# nrf9220_cellcore register map
Vendor: Nordic Semiconductor; Series: nRF92; File version: 1
CPU: CM33 r0p4, little endian, MPU, FPU, 3 interrupt priority bits, 480 interrupts, 8 SAU regions
Registers are 32-bit, read-write, reset 0x0 unless marked. A register's access mark holds for its fields unless they carry their own. Offsets are from the block's base; [hi:lo] are bit positions; lines under a group give offsets from that group; {n}, {i} and the like mark numbered series.

## LFCLKCALIBMEAS_NS — LFCLK calibration measurement 0
Base 0x44023000
Same registers: LFCLKCALIBMEAS_S 0x54023000
0x00 TASKS_START wo — Start Measuring
  [0] TASKS_START
    1=Trigger task
0x04 TASKS_STOP wo — Switch LfClkCalibMeas to STOPPED state. Brings LfClkCalibMeas from SHUTDOWN state to a configurable state before a measurement is launched.
  [0] TASKS_STOP
    1=Trigger task
0x08 TASKS_SHUTDOWN wo — Shut down LfClkCalibMeas
  [0] TASKS_SHUTDOWN
    1=Trigger task
0x100 EVENTS_COMPLETE — Measurement completed
  [0] EVENTS_COMPLETE
    0=NotGenerated (Event not generated); 1=Generated (Event generated)
0x300 INTEN — Enable or disable interrupt
  [0] COMPLETE — Enable or disable interrupt for event COMPLETE
    0=Disabled; 1=Enabled
0x304 INTENSET — Enable interrupt
  [0] COMPLETE — Write '1' to enable interrupt for event COMPLETE
    on read: 0=Disabled (Read: Disabled); 1=Enabled (Read: Enabled) | on write: 1=Set (Enable)
0x308 INTENCLR — Disable interrupt
  [0] COMPLETE — Write '1' to disable interrupt for event COMPLETE
    on read: 0=Disabled (Read: Disabled); 1=Enabled (Read: Enabled) | on write: 1=Clear (Disable)
0x30C INTPEND ro — Pending interrupts
  [0] COMPLETE — Read pending status of interrupt for event COMPLETE
    on read: 0=NotPending (Read: Not pending); 1=Pending (Read: Pending)
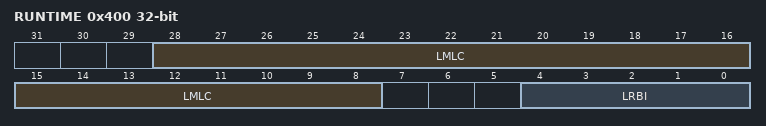
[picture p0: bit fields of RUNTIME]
0x400 RUNTIME ro — Runtime status of the measurement
  [28:8] LMLC — lastMeasuredLfCycle
  [4:0] LRBI — LastRingBufferIndex
{0x404+4i} LCMEAS[{i}] (i=0..19) group — Unspecified
  0x00 LCMEAS ro — Description cluster: LfClk measurement result for the series n
    [31:0] LCMEAS — LfClk measurement result for the series n
0x47C STATE ro — Current running state of the IP
  [1:0] STATE
    0=Shutdown (In SHUTDOWN state); 1=Stopped (In STOPPED state); 2=Running (In RUNNING state); 3=NotApplicable
0x500 MEASLEN — Length of the measurement
  [20:0] MEASLEN

## TIMEREVENTSYNCH_NS — Timer event synchronizer 0
Base 0x44024000
Same registers: TIMEREVENTSYNCH_S 0x54024000
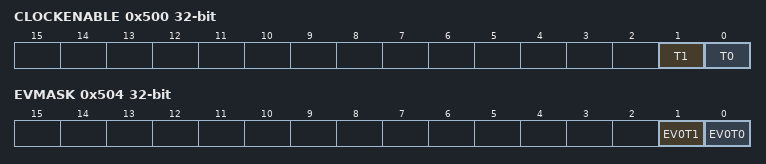
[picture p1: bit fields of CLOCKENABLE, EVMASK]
0x500 CLOCKENABLE — Enable synchronizer clock
  [1] T1 — Enable for clock ck_t1
    0=Disable clock ck_t1; 1=Enable clock ck_t1
  [0] T0 — Enable for clock ck_t0
    0=Disable clock ck_t0; 1=Enable clock ck_t0
0x504 EVMASK — Event mask
  [1] EV0T1 — Mask control for event 0 and output t1
    0=Disable (Event 0 is not propagated to output t1); 1=Enable (Event 0 is propagated to output t1)
  [0] EV0T0 — Mask control for event 0 and output t0
    0=Disable (Event 0 is not propagated to output t0); 1=Enable (Event 0 is propagated to output t0)

## TIMEMARKMUX0_NS — Timemark multiplexer 0
Base 0x44025000
Same registers: TIMEMARKMUX1_NS 0x44034000, TIMEMARKMUX2_NS 0x44038000, TIMEMARKMUX0_S 0x54025000, TIMEMARKMUX1_S 0x54034000, TIMEMARKMUX2_S 0x54038000
0x500 OUTPUTENABLE — Enable Timemark Mux
  [0] ENABLE
    0=Disable timemark output; 1=Enable timemark output
0x504 TIMEMARKSELECT — Timemark input select register
  [7:0] TIMEMARKSELECT — Timemark input select
    1=Event0 (Enable compareEventsIn[0] as timemark input); 2=Event1 (Enable compareEventsIn[1] as timemark input); 4=Event2 (Enable compareEventsIn[2] as timemark input); 8=Event3 (Enable compareEventsIn[3] as timemark input); 16=Event4 (Enable compareEventsIn[4] as timemark input); 32=Event5 (Enable compareEventsIn[5] as timemark input); 64=Event6 (Enable compareEventsIn[6] as timemark input); 128=Event7 (Enable compareEventsIn[7] as timemark input)

## CELLCORETIMERPDCTRL_NS — Cellular core TIMERPD FSM control
Base 0x54036500; alternate view of PCGCS3_S
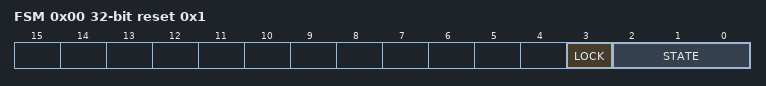
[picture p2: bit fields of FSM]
0x00 FSM reset 0x1 — Timer power domain finite state machine control
  [3] LOCK — Lock the state of TIMERFSM.
    0=UNLOCKED (FSM not locked.); 1=LOCKED (FSM locked.)
  [2:0] STATE — TIMERFSM state
    0=GUARD_TIMERPD_BRIDGE (Power requested for PD_TIMERS_ACT. Intermediate state between MCPLL_OFF and TIMERPD_GOING_OFF.); 1=TIMERPD_RESET (Power requested for PD_TIMERS_ACT. State after power domain reset.); 2=TIMERPD_GOING_ON (Power requested for PD_TIMERS_ACT. PD_TIMERS_ACT powering up. Intermediate state before MCPLL_OFF.); 3=MCPLL_ON (Power requested for PD_TIMERS_ACT. MCPLL clock requested.); 4=MCPLL_OFF (Power requested for PD_TIMERS_ACT. MCPLL clock not requested.); 5=TIMERPD_GOING_OFF (Power requested for PD_TIMERS_ACT. Intermediate state before TIMERPD_OFF.); 6=TIMERPD_OFF (No power requested for PD_TIMERS_ACT.)

## Notices in the file
Copyright (c) 2010 - 2025, Nordic Semiconductor ASA
All rights reserved.
Redistribution and use in source and binary forms, with or without modification,
are permitted provided that the following conditions are met:
1. Redistributions of source code must retain the above copyright notice, this
list of conditions and the following disclaimer.
2. Redistributions in binary form, except as embedded into a Nordic
Semiconductor ASA integrated circuit in a product or a software update for
such product, must reproduce the above copyright notice, this list of
conditions and the following disclaimer in the documentation and/or other
materials provided with the distribution.
3. Neither the name of Nordic Semiconductor ASA nor the names of its
contributors may be used to endorse or promote products derived from this
software without specific prior written permission.
4. This software, with or without modification, must only be used with a
Nordic Semiconductor ASA integrated circuit.
5. Any software provided in binary form under this license must not be reverse
engineered, decompiled, modified and/or disassembled.
THIS SOFTWARE IS PROVIDED BY NORDIC SEMICONDUCTOR ASA "AS IS" AND ANY EXPRESS
OR IMPLIED WARRANTIES, INCLUDING, BUT NOT LIMITED TO, THE IMPLIED WARRANTIES
OF MERCHANTABILITY, NONINFRINGEMENT, AND FITNESS FOR A PARTICULAR PURPOSE ARE
DISCLAIMED. IN NO EVENT SHALL NORDIC SEMICONDUCTOR ASA OR CONTRIBUTORS BE
LIABLE FOR ANY DIRECT, INDIRECT, INCIDENTAL, SPECIAL, EXEMPLARY, OR
CONSEQUENTIAL DAMAGES (INCLUDING, BUT NOT LIMITED TO, PROCUREMENT OF SUBSTITUTE
GOODS OR SERVICES; LOSS OF USE, DATA, OR PROFITS; OR BUSINESS INTERRUPTION)
HOWEVER CAUSED AND ON ANY THEORY OF LIABILITY, WHETHER IN CONTRACT, STRICT
LIABILITY, OR TORT (INCLUDING NEGLIGENCE OR OTHERWISE) ARISING IN ANY WAY OUT
OF THE USE OF THIS SOFTWARE, EVEN IF ADVISED OF THE POSSIBILITY OF SUCH DAMAGE.
